# RTS591x register map
Vendor: Realtek Semiconductor Corp.; Series: RTS591x Series; File version: 1.0
CPU: ARMV8MML r0p0, little endian, MPU, FPU, VTOR, 3 interrupt priority bits, 4 SAU regions
Registers are 32-bit, read-write, reset 0x0 unless marked. A register's access mark holds for its fields unless they carry their own. Offsets are from the block's base; [hi:lo] are bit positions; {n}, {i} and the like mark numbered series.

## SHA2 — Lalu SHA2 Engine
Base 0x40000000
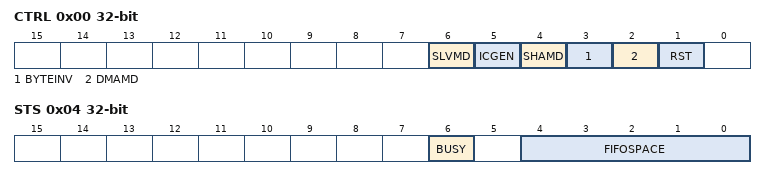
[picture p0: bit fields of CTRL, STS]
0x00 CTRL — CONTROL REGISTER
  [6] SLVMD — Slave Mode/DMA Mode Selection
    0=DMA (Select DMA mode); 1=SLV (Select slave mode)
  [5] ICGEN — Enable Auto Clock Gating
    0=DISABLE (Disable ICG); 1=ENABLE (Enable ICG)
  [4] SHAMD — SHA Mode Selection
    0=SHA224_256 (Select SHA224/256); 1=SHA384_512 (Select SHA384/512)
  [3] BYTEINV — Inverse Byte Order or Not
    0=NATIVE (Select native byte order); 1=INVERSE (Select inverse byte order)
  [2] DMAMD — DMA Mode Selection
    0=RD_ONLY (Select read-only mode); 1=COPY (Select copy mode)
  [1] RST — Reset Digest Registers
    0=DO_NOTHING; 1=RESET (Reset digest registers)
0x04 STS ro — STATUS REGISTER
  [6] BUSY — Engine Busy Bit
    0=IDLE (Engine is idle); 1=BUSY (Engine is busy)
  [4:0] FIFOSPACE — Number Of Available FIFO Space In Byte
{0x10+4i} DIGEST[{i}] (i=0..15) — DEGIEST REGISTER
0x50 FIFOIN — FIFO INPUT DATA REGISTER

## SHA2DMA — Lalu SHA2 DMA Controller
Base 0x40001000
Same registers: AESDMA 0x40004000
0x00 SAR — SOURCE ADDRESS REGISTER
0x08 DAR — DESTINATION ADDRESS REGISTER
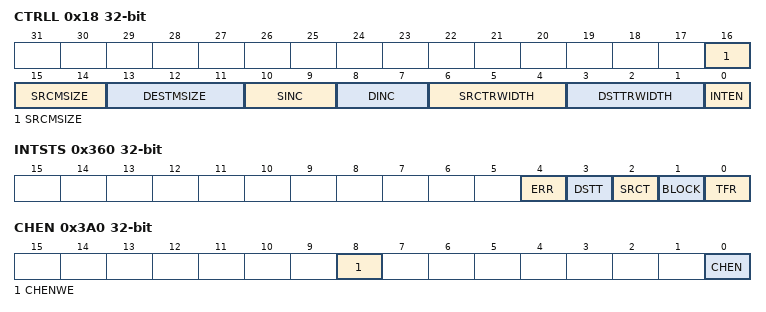
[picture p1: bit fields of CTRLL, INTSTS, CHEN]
0x18 CTRLL — CONTROL REGISTER LOW
  [16:14] SRCMSIZE — Source Burst Transaction Length
  [13:11] DESTMSIZE — Destination Burst Transaction Length
  [10:9] SINC — Source Address Increment
  [8:7] DINC — Destination Address Increment
  [6:4] SRCTRWIDTH — Source Transfer Width
  [3:1] DSTTRWIDTH — Destination Transfer Width
  [0] INTEN — Interrupt Enable Bit
    0=DISABLE (Disable interrup); 1=ENABLE (Enable interrup)
0x1C CTRLH — CONTROL REGISTER HIGH
  [11:0] BLOCKTS — Block Transfer Size
0x44 CFG — CONFIGURATION REGISTER
  [3] PROTCTL — Protection Control
0x310 MSKTFR — MASK FOR INTTFR INTERRUPT REGISTER
0x338 CLRTFR — CLEAR INTERRUPT STATUS FOR INTTFR INTERRUPT REGISTER
0x360 INTSTS ro — COMBINED INTERRUPT SATAUS REGISTER
  [4] ERR — OR of The Contents of StatusErr Register
  [3] DSTT — OR of The Contents of StatusDst Register
  [2] SRCT — OR of The Contents of StatusSrcTran Register
  [1] BLOCK — OR of The Contents of StatusBlock Register
  [0] TFR — OR of The Contents of StatusTfr Register
0x398 CONF — CONFIGURATION REGISTER
  [0] EN — Enable DMA Controller
    0=DISABLE (Disable DMA Controller); 1=ENABLE (Enable DMA Controller)
0x3A0 CHEN — CHANNEL ENABLE REGISTER
  [8] CHENWE — Enables Channel Write Enable
    0=DISABLE (Dsiable channel write enable); 1=ENABLE (Enables channel write enable)
  [0] CHEN — Enables DMA Channel
    0=DISABLE (Dsiable DMA Channel); 1=ENABLE (Enables DMA Channel)

## SHA3 — Lalu SHA3 Engine
Base 0x40002000
0x00 ADDR — START ADDRESS REGISTER
0x04 LEN — DATA LENGTH REGISTER
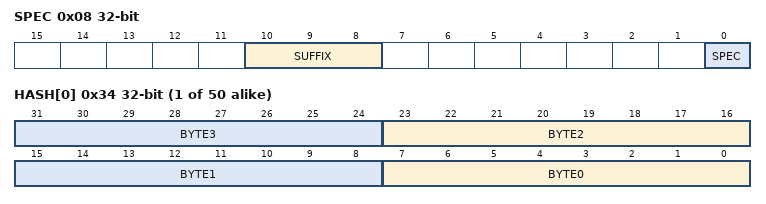
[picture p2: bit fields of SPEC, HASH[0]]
0x08 SPEC — SPECIFICATION REGISTER
  [10:8] SUFFIX — Suffix Of SHA3 Specification
    0=SHAKE128 (Select SHAKE128); 1=SHA3_224 (Select SHA3-224); 2=SHA3_256 (Select SHA3-256); 3=SHA3_384 (Select SHA3-384); 4=SHA3_512 (Select SHA3-512)
  [0] SPEC — SHA3 Or SHAKE Selection
    0=SHA3 (Select SHA3); 1=SHAKE (Select SHAKE)
0x0C INTDIS — INTERRUPT DISABLE REGISTER
0x10 LPMDDIS — LOW POWER MODE DISABLE REGISTER
0x14 ENABLE
  [10:8] EN — Enable SHA3 Engine To Execute Command
    1=UPDATE (SHA3 engine DMA starts to receive input data); 2=FINALIZE (SHA3 engine attches padding data and generate HASH data); other=NOT_USED (Reserved values. Do not use.)
0x18 CLR — CLEAR HASH VALUE AND INPUT BUFFER REGISTER
0x1C CLRINT — CLEAR INTERRUPT REGISTER
0x20 SQUEEZE
0x24 INTSTS — INTERRUPT STATUS REGISTER
0x2C RDERRSTS — READ ERROR STATUS REGISTER
0x30 ADDRERR — READ ERROR ADDRESS REGISTER
{0x34+4i} HASH[{i}] (i=0..49) — HASH VALUE REGISTER
  [8n+7:8n] BYTE{n} (n=0..3) — Hash value, byte{n}
